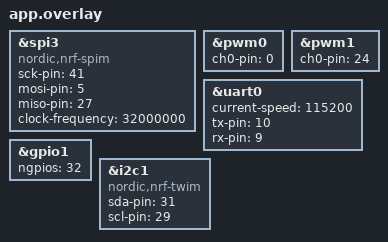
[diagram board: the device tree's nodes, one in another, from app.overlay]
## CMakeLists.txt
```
# SPDX-License-Identifier: Apache-2.0

cmake_minimum_required(VERSION 3.13.1)

find_package(Zephyr REQUIRED HINTS $ENV{ZEPHYR_BASE})
project(hello_world)

target_sources(app PRIVATE src/main.cpp src/display.cpp src/controller.cpp src/console.cpp src/sound.cpp src/invaders.cpp src/sprite.cpp src/mesh.c)
```

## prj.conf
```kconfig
# Incresed stack due to settings API usage
CONFIG_SYSTEM_WORKQUEUE_STACK_SIZE=2048
CONFIG_MAIN_STACK_SIZE=4096


CONFIG_BT=y
CONFIG_BT_DEBUG_LOG=y
# Security manager protocol support for pairing
CONFIG_BT_SMP=y
# used to sign authenticated data
CONFIG_BT_SIGNING=y
# select peripheral role
CONFIG_BT_PERIPHERAL=n

# enable GATT device information service
CONFIG_BT_DIS=n
# number of buffers available for GATT writing
CONFIG_BT_ATT_PREPARE_COUNT=5


# enables local privacy feature support (Random MAC)
CONFIG_BT_PRIVACY=n
# name that appears when browsing
CONFIG_BT_DEVICE_NAME="DublinMaker"

# 0x4c0 = generic control device = 1216
CONFIG_BT_DEVICE_APPEARANCE=1216
# disable updating of device name to prevent use of generic name
# disable run-time changing of device name
CONFIG_BT_DEVICE_NAME_DYNAMIC=n
# CONFIG_BT_DEVICE_NAME_MAX=65
CONFIG_BT_OBSERVER=y
CONFIG_BT_KEYS_OVERWRITE_OLDEST=y

CONFIG_BT_RX_STACK_SIZE=1280
CONFIG_BT_CTLR_DUP_FILTER_LEN=0
CONFIG_BT_OBSERVER=y
CONFIG_BT_BROADCASTER=y
CONFIG_BT_PHY_UPDATE=n
CONFIG_BT_DATA_LEN_UPDATE=n

CONFIG_BT_MESH=y
CONFIG_BT_MESH_RELAY=y
CONFIG_BT_MESH_SEG_BUFS=10
CONFIG_BT_MESH_SUBNET_COUNT=1
CONFIG_BT_MESH_APP_KEY_COUNT=2
CONFIG_BT_MESH_MODEL_GROUP_COUNT=2
CONFIG_BT_MESH_ADV_BUF_COUNT=3
CONFIG_BT_MESH_LOOPBACK_BUFS=8
CONFIG_BT_MESH_PB_ADV=n
CONFIG_BT_MESH_CFG_CLI=y
CONFIG_BT_MESH_BEACON_ENABLED=n
CONFIG_BT_MESH_RPL_STORE_TIMEOUT=600
CONFIG_BT_MESH_DEBUG=y

CONFIG_BT_SETTINGS=n
CONFIG_FLASH=y
CONFIG_FLASH_PAGE_LAYOUT=y
CONFIG_FLASH_MAP=y
CONFIG_NVS=y
CONFIG_SETTINGS=y



# enable SPI and GPIO
CONFIG_SPI=y
CONFIG_SPI_NRFX=y
CONFIG_GPIO=y
CONFIG_PWM=y
# By default P0.10 and P0.9 are configured for NFC and so not available for GPIO/UART use.  
# This switches them back to GPIO
CONFIG_NFCT_PINS_AS_GPIOS=y
# This doesn't seem to be working
CONFIG_GPIO_AS_PINRESET=n

# enable uart driver
CONFIG_SERIAL=y

# enable console
CONFIG_CONSOLE=y
CONFIG_UART_CONSOLE=y

CONFIG_CLOCK_CONTROL_NRF_K32SRC_RC=y
CONFIG_I2C=y

CONFIG_PM=n
CONFIG_HEAP_MEM_POOL_SIZE=8192
```

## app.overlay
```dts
&spi3 {
 compatible = "nordic,nrf-spim";
 status = "okay";
 sck-pin = <41>; // P1.09
 mosi-pin = <5>; // P0.05
 /* Redirecting MISO to a pin that is not connected on the microbit v2 board */
 miso-pin = <27>;
 clock-frequency = <32000000>;
};
&pwm0 {
	status = "okay";
	ch0-pin = <0>; 	
};
&pwm1 {
	status = "okay";
	ch0-pin = <24>; 	
};
&uart0 {
        status = "okay";
        current-speed = <115200>;
        tx-pin = <10>;
        rx-pin = <9>;
};

&gpio1 {
       status = "okay";
       ngpios = <32>;

};
&i2c1 {
	compatible = "nordic,nrf-twim";
    status = "okay";
    sda-pin = <31>; // P0.31 SDA on SAO connector
    scl-pin = <29>; // P0.29 SCL on SAO connector
};
```

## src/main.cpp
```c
#include <zephyr.h>
#include <sys/printk.h>

#include <settings/settings.h>

#include <bluetooth/bluetooth.h>
#include <bluetooth/mesh.h>
#include <bluetooth/hci.h>
#include <bluetooth/conn.h>
#include <bluetooth/uuid.h>
#include <bluetooth/gatt.h>
#include <drivers/pwm.h>
#include "display.h"
#include "controller.h"
#include "console.h"
#include "sound.h"
#include "invaders.h"
#include "mesh.h"

void sao_test()
{
	/* P0.24 - test ok, 
	 * P0.13 - test ok,
	 * P0.18 - NOT OK
	 * POWER subsystem at offset 0x40000000
	 * PSELRESET0 at offset 200
	 * PSELRESET1 at offset 204
	 * P1.09 - test ok
	*/
	static const struct device *gpio0,*gpio1;
	uint32_t * pselreset0 = (uint32_t *)0x40000200;
	uint32_t * pselreset1 = (uint32_t *)0x40000204; 
	*pselreset0=0x80000000;
	*pselreset1=0x80000000;
	gpio0=device_get_binding("GPIO_0");
	gpio1=device_get_binding("GPIO_1");
	gpio_pin_configure(gpio0,18,GPIO_OUTPUT);
	
	printk("0 = %x ",*pselreset0);
	printk("1 = %x\n",*pselreset1);
	while(1)
	{
		gpio_pin_set(gpio0,18,1);
		k_msleep(100);
		gpio_pin_set(gpio0,18,0);
		k_msleep(100);
	}
	
}
extern console Console;
#define TILE_WIDTH 30
#define TILE_HEIGHT 30
#define SPRITE_WIDTH 20
#define SPRITE_HEIGHT 25
const uint16_t tile[]={
0,
0,
0,
0,
0,
0,
0,
0,
0,
0,
0,
0,
0,
0,
0,
0,
0,
0,
0,
0,
0,
0,
0,
0,
0,
0,
0,
0,
0,
0,
0,
0,
0,
0,
0,
0,
0,
0,
0,
0,
0,
0,
0,
0,
0,
0,
0,
0,
0,
0,
0,
0,
0,
0,
0,
0,
0,
0,
0,
0,
248,
248,
248,
248,
248,
248,
248,
248,
248,
248,
248,
248,
248,
248,
248,
248,
248,
248,
248,
248,
248,
248,
248,
248,
248,
248,
248,
248,
248,
248,
248,
248,
248,
248,
248,
248,
248,
248,
248,
248,
248,
248,
248,
248,
248,
248,
248,
248,
248,
248,
248,
248,
248,
248,
248,
248,
248,
248,
248,
248,
57599,
57599,
57599,
57599,
57599,
57599,
57599,
57599,
57599,
57599,
57599,
57599,
57599,
57599,
57599,
57599,
57599,
57599,
57599,
57599,
57599,
57599,
57599,
57599,
57599,
57599,
57599,
57599,
57599,
57599,
57599,
57599,
57599,
57599,
57599,
57599,
57599,
57599,
57599,
57599,
57599,
57599,
57599,
57599,
57599,
57599,
57599,
57599,
57599,
57599,
57599,
57599,
57599,
57599,
57599,
57599,
57599,
57599,
57599,
57599,
57351,
57351,
57351,
57351,
57351,
57351,
57351,
57351,
57351,
57351,
57351,
57351,
57351,
57351,
57351,
57351,
57351,
57351,
57351,
57351,
57351,
57351,
57351,
57351,
57351,
57351,
57351,
57351,
57351,
57351,
57351,
57351,
57351,
57351,
57351,
57351,
57351,
57351,
57351,
57351,
57351,
57351,
57351,
57351,
57351,
57351,
57351,
57351,
57351,
57351,
57351,
57351,
57351,
57351,
57351,
57351,
57351,
57351,
57351,
57351,
65287,
65287,
65287,
65287,
65287,
65287,
65287,
65287,
65287,
65287,
65287,
65287,
65287,
65287,
65287,
65287,
65287,
65287,
65287,
65287,
65287,
65287,
65287,
65287,
65287,
65287,
65287,
65287,
65287,
65287,
65287,
65287,
65287,
65287,
65287,
65287,
65287,
65287,
65287,
65287,
65287,
65287,
65287,
65287,
65287,
65287,
65287,
65287,
65287,
65287,
65287,
65287,
65287,
65287,
65287,
65287,
65287,
65287,
65287,
65287,
7936,
7936,
7936,
7936,
7936,
7936,
7936,
7936,
7936,
7936,
7936,
7936,
7936,
7936,
7936,
7936,
7936,
7936,
7936,
7936,
7936,
7936,
7936,
7936,
7936,
7936,
7936,
7936,
7936,
7936,
7936,
7936,
7936,
7936,
7936,
7936,
7936,
7936,
7936,
7936,
7936,
7936,
7936,
7936,
7936,
7936,
7936,
7936,
7936,
7936,
7936,
7936,
7936,
7936,
7936,
7936,
7936,
7936,
7936,
7936,
8184,
8184,
8184,
8184,
8184,
8184,
8184,
8184,
8184,
8184,
8184,
8184,
8184,
8184,
8184,
8184,
8184,
8184,
8184,
8184,
8184,
8184,
8184,
8184,
8184,
8184,
8184,
8184,
8184,
8184,
8184,
8184,
8184,
8184,
8184,
8184,
8184,
8184,
8184,
8184,
8184,
8184,
8184,
8184,
8184,
8184,
8184,
8184,
8184,
8184,
8184,
8184,
8184,
8184,
8184,
8184,
8184,
8184,
8184,
8184,
4348,
4348,
4348,
4348,
4348,
4348,
4348,
4348,
4348,
4348,
4348,
4348,
4348,
4348,
4348,
4348,
4348,
4348,
4348,
4348,
4348,
4348,
4348,
4348,
4348,
4348,
4348,
4348,
4348,
4348,
4348,
4348,
4348,
4348,
4348,
4348,
4348,
4348,
4348,
4348,
4348,
4348,
4348,
4348,
4348,
4348,
4348,
4348,
4348,
4348,
4348,
4348,
4348,
4348,
4348,
4348,
4348,
4348,
4348,
4348,
61575,
61575,
61575,
61575,
61575,
61575,
61575,
61575,
61575,
61575,
61575,
61575,
61575,
61575,
61575,
61575,
61575,
61575,
61575,
61575,
61575,
61575,
61575,
61575,
61575,
61575,
61575,
61575,
61575,
61575,
61575,
61575,
61575,
61575,
61575,
61575,
61575,
61575,
61575,
61575,
61575,
61575,
61575,
61575,
61575,
61575,
61575,
61575,
61575,
61575,
61575,
61575,
61575,
61575,
61575,
61575,
61575,
61575,
61575,
61575,
6342,
6342,
6342,
6342,
6342,
6342,
6342,
6342,
6342,
6342,
6342,
6342,
6342,
6342,
6342,
6342,
6342,
6342,
6342,
6342,
6342,
6342,
6342,
6342,
6342,
6342,
6342,
6342,
6342,
6342,
6342,
6342,
6342,
6342,
6342,
6342,
6342,
6342,
6342,
6342,
6342,
6342,
6342,
6342,
6342,
6342,
6342,
6342,
6342,
6342,
6342,
6342,
6342,
6342,
6342,
6342,
6342,
6342,
6342,
6342,
128,
128,
128,
128,
128,
128,
128,
128,
128,
128,
128,
128,
128,
128,
128,
128,
128,
128,
128,
128,
128,
128,
128,
128,
128,
128,
128,
128,
128,
128,
128,
128,
128,
128,
128,
128,
128,
128,
128,
128,
128,
128,
128,
128,
128,
128,
128,
128,
128,
128,
128,
128,
128,
128,
128,
128,
128,
128,
128,
128,
8068,
8068,
8068,
8068,
8068,
8068,
8068,
8068,
8068,
8068,
8068,
8068,
8068,
8068,
8068,
8068,
8068,
8068,
8068,
8068,
8068,
8068,
8068,
8068,
8068,
8068,
8068,
8068,
8068,
8068,
8068,
8068,
8068,
8068,
8068,
8068,
8068,
8068,
8068,
8068,
8068,
8068,
8068,
8068,
8068,
8068,
8068,
8068,
8068,
8068,
8068,
8068,
8068,
8068,
8068,
8068,
8068,
8068,
8068,
8068,
252,
252,
252,
252,
252,
252,
252,
252,
252,
252,
252,
252,
252,
252,
252,
252,
252,
252,
252,
252,
252,
252,
252,
252,
252,
252,
252,
252,
252,
252,
252,
252,
252,
252,
252,
252,
252,
252,
252,
252,
252,
252,
252,
252,
252,
252,
252,
252,
252,
252,
252,
252,
252,
252,
252,
252,
252,
252,
252,
252,
4228,
4228,
4228,
4228,
4228,
4228,
4228,
4228,
4228,
4228,
4228,
4228,
4228,
4228,
4228,
4228,
4228,
4228,
4228,
4228,
4228,
4228,
4228,
4228,
4228,
4228,
4228,
4228,
4228,
4228,
4228,
4228,
4228,
4228,
4228,
4228,
4228,
4228,
4228,
4228,
4228,
4228,
4228,
4228,
4228,
4228,
4228,
4228,
4228,
4228,
4228,
4228,
4228,
4228,
4228,
4228,
4228,
4228,
4228,
4228,
65287,
65287,
65287,
65287,
65287,
65287,
65287,
65287,
65287,
65287,
65287,
65287,
65287,
65287,
65287,
65287,
65287,
65287,
65287,
65287,
65287,
65287,
65287,
65287,
65287,
65287,
65287,
65287,
65287,
65287,
65287,
65287,
65287,
65287,
65287,
65287,
65287,
65287,
65287,
65287,
65287,
65287,
65287,
65287,
65287,
65287,
65287,
65287,
65287,
65287,
65287,
65287,
65287,
65287,
65287,
65287,
65287,
65287,
65287,
65287,
};
void drawTile(int row, int col)
{
	Console.Display.putImage(row*TILE_WIDTH,col*TILE_HEIGHT,TILE_WIDTH,TILE_HEIGHT,(uint16_t *)&tile[0]);
}
void drawTile2(int row, int col)
{
	Console.Display.fillRectangle(row*TILE_WIDTH,col*TILE_HEIGHT,TILE_WIDTH,TILE_HEIGHT,0xffff);
}
void drawLandscape()
{

	int row,col;
	
	for (row=0;row<SCREEN_HEIGHT/TILE_HEIGHT;row++)
	{
		for (col=0;col<SCREEN_WIDTH/TILE_WIDTH;col++)
		{
			drawTile(row,col);
		}
	}
}

uint8_t dirty_flags[]={0,0,0,0,0,0,0,0};
void flagDirty(int row, int col)
{
	dirty_flags[row] |= (1 << col);
}
void flagClean(int row, int col)
{
	dirty_flags[row] &= ~(1 << col);
}
int isDirty(int row, int col)
{
	if (dirty_flags[row] & (1 << col))
		return 1;
	else
		return 0;
}
void check_for_overlap(int x,int y, int w, int h)
{
	// incoming arguments are the bounding rectangle for a sprite
	// This function checks to see if that sprite overlaps each
	// background screen tile.
	int row,col;
	for (row=0;row<SCREEN_HEIGHT/TILE_HEIGHT;row++)
	{
		for (col=0;col<SCREEN_WIDTH/TILE_WIDTH;col++)
		{
			
			// check top left corner
			if ((x >=row*TILE_WIDTH) && (y >= col*TILE_HEIGHT) &&
				((x) < (row+1)*TILE_WIDTH) && ((y) < (col+1)*TILE_HEIGHT) )
			{
				flagDirty(row,col);				
			}
			// check top right
			if (((x+w) >=row*TILE_WIDTH) && (y >= col*TILE_HEIGHT) &&
				((x+w) < (row+1)*TILE_WIDTH) && ((y) < (col+1)*TILE_HEIGHT) )
			{
				flagDirty(row,col);				
			}
			// check bottom left corner
			if ((x >=row*TILE_WIDTH) && ((y+h) >= col*TILE_HEIGHT) &&
				((x) < (row+1)*TILE_WIDTH) && ((y+h) < (col+1)*TILE_HEIGHT) )
			{
				flagDirty(row,col);				
			}
			// check bottom right
			if (((x+w) >=row*TILE_WIDTH) && ((y+w) >= col*TILE_HEIGHT) &&
				((x+w) < (row+1)*TILE_WIDTH) && ((y+w) < (col+1)*TILE_HEIGHT) )
			{
				flagDirty(row,col);				
			}
		}
	}	
}
void drawCharacter(int x, int y)
{
	
	// 1f00 = blue
	// 00f8 = red
	// e007 = green
	
	Console.Display.fillRectangle(x,y,SPRITE_WIDTH,SPRITE_HEIGHT,4);
}
void moveCharacter()
{
	int x,y;
	int row,col;
	x = 0; y = 0;
	while(1)
	{

		for (row=0;row<SCREEN_HEIGHT/TILE_HEIGHT;row++)
		{
			for (col=0;col<SCREEN_WIDTH/TILE_WIDTH;col++)
			{
				if (isDirty(row,col))
				{
					drawTile(row,col);
					flagClean(row,col);
				}
			}
		}		
		drawCharacter(x,y);
		k_msleep(70);
		check_for_overlap(x,y,SPRITE_WIDTH,SPRITE_HEIGHT);
		x++;
		if (x >= (SCREEN_WIDTH-SPRITE_WIDTH))
			x=0;
		y++;
		if (y >= (SCREEN_HEIGHT-SPRITE_HEIGHT))
			y = 0;
		
	}
}
void main(void)
{
	
	
	int ret;
	int count=0;	
	ret = Console.begin();	
	uint8_t msg_count = 0;
	mesh_begin();
	if (ret < 0)
	{
		printk("\nError initializing console.  Error code = %d\n",ret);
		while(1);
	}	
	//playInvaders(0);		
	drawLandscape();
	moveCharacter();
	while(1)
	{
		
		//printk("Hello World! %s\n", CONFIG_BOARD);
       //Display.drawRectangle(random(0,119),random(0,119),random(0,120),random(0,120),random(0,0xffff));                                
       //Console.Display.fillRectangle(Console.random(0,240),Console.random(0,240),Console.random(0,240),Console.random(0,240),Console.random(0,0xffff));                   
       // display_drawCircle(random(0,240),random(0,240),random(0,135),random(0,0xffff));
        //Display.fillCircle(random(0,240),random(0,135),random(0,120),random(0,0xffff));
        count++;
        if (count >= 50) 
        {
            //Console.Display.fillRectangle(0,0,SCREEN_WIDTH,SCREEN_HEIGHT,0);
			
		//	Console.Display.print("Starting over",sizeof("Starting over")-1,20,60,0xffff,0);
            count = 0;
		//	sendDMBMessage(msg_count++);

			//printk("restarting\n");
			printk("Buttons = %x\n",Console.Controller.getButtonState());
 		//	printk("Buttons = %d\r\n",Console.Controller.getButtonState());
        }
        
	}
}
```

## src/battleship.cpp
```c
#include <zephyr.h>
#include <sys/printk.h>
#include "mesh.h"
#include "display.h"
#include "console.h"
#include "controller.h"
#include "battleship.h"
#include "font5x7.h"
void ship::place(int len, int row, int col, int orientation)
{
    this->len = len;
    this->row = row;
    this->col = col;
    this->orientation = orientation;
    
    state = 0;
}
int ship::contains(int row, int col)
{
    // returns 1 if the ship occupies the square at this row, column
    // otherwise returns 0
    int return_value = 0;
    if (orientation == 0)
    {
        // Horizontal
        if (this->row == row) 
        {
            // same row.
            if ( (col >= this->col) && (col < (this->col+this->len)))
                return_value = 1; // it is within
        }
    }
    else
    {
        // Vertical
        if (this->col == col)
        {
            if ( (row >= this->row) && (row < (this->row+this->len)))
                return_value = 1; // it is within
        }
    }
    return return_value; // not within the bounds of this ship
}
int ship::overlaps(int len, int row, int col, int orientation)
{
    // returns 1 if the ship described by the parameters overlaps
    // this ship - uses for initial ship placement.
    // otherwise returns 0
    int return_value = 0;
    if (orientation == 0)
    {
        // Horizontal
        for (int count = 0; count < len; count++)
        {
            if (this->contains(row,col+count))
                return_value = 1;
        }
    }
    else
    {
        // Vertical
        for (int count = 0; count < len; count++)
        {
            if (this->contains(row+count,col))
                return_value = 1;
        }
    }
    return return_value;
}
/* each square can have the following properties:
 * Empty
 * Your ship (ship_id with particular bit pattern for you/them)
 * Their ship
 * Your ship hit
 * Their ship hit
 * uint8_t my_ship_map[10][10];
 */

void battleship()
{
    int row,col;
    uint8_t map[10][10];
    int ship_counter = 0;
    int Done=0;
    uint16_t target=0;
    int my_ship_hit_counter = 0;
    int their_ship_hit_counter = 0;
    int total_hits;
    total_hits = (CARRIER_COUNT*CARRIER_SQUARES) + (BATTLESHIP_COUNT*BATTLESHIP_SQUARES)+(SUBMARINE_COUNT*SUBMARINE_SQUARES)+(PATROL_BOAT_COUNT*PATROL_BOAT_SQUARES); 
	mesh_clearReplay();

    Console.Display.clear();
    Console.Display.printX2("Target node: ", 13,0,0,Console.Display.RGBToWord(0xff,0xff,0), Console.Display.RGBToWord(0,0,0) );
    while(!Done)
    {
        Console.Display.printX2(target,0,1+FONT_HEIGHT*2, Console.Display.RGBToWord(0xff,0xff,0), Console.Display.RGBToWord(0,0,0) );
        uint16_t key=0;
        while(key == 0)
        {
            key=Console.Controller.getButtonState();
            k_msleep(50);
        }
        switch(key)
        {
            case Console.Controller.Up :
            {
                target++;
                break;
            }
            case Console.Controller.Down :
            {
                target--;
                break;
            }
            case Console.Controller.A :
            {
                Done=1;
                break;
            }
            case Console.Controller.B :
            {
                Done=2;
                break;
            }
        }
        k_msleep(100);
    }

    ship Ships[CARRIER_COUNT+BATTLESHIP_COUNT+SUBMARINE_COUNT+PATROL_BOAT_COUNT];
    Console.Display.clear();
    
    for (row=0;row<10;row++)
    {
        Console.Display.drawLine(0,row*(SCREEN_HEIGHT/10),SCREEN_WIDTH,row*(SCREEN_HEIGHT/10),Console.Display.RGBToWord(0xf,0xf,0xff));
    }
    for (col=0;col<10;col++)
    {
        Console.Display.drawLine(col*(SCREEN_WIDTH/10),0,col*(SCREEN_WIDTH/10),SCREEN_HEIGHT,Console.Display.RGBToWord(0xf,0xf,0xff));
    }
    Console.Display.drawLine(0,SCREEN_HEIGHT-1,SCREEN_WIDTH-1,SCREEN_HEIGHT-1,Console.Display.RGBToWord(0xf,0xf,0xff));
    Console.Display.drawLine(SCREEN_WIDTH-1,0,SCREEN_WIDTH-1,SCREEN_HEIGHT-1,Console.Display.RGBToWord(0xf,0xf,0xff));
    for (row=0;row<10;row++)
    {
        for (col=0;col<10;col++)
            map[row][col]=0;
    }
    // start placing ships
    // Aircraft carrier first as it will be hardest to position.
    int orientation = Console.random(0,2);
    if (orientation == 0)
    {
        // Horizontal
        col=Console.random(0,CARRIER_SQUARES);
        row=Console.random(0,10);
        for (int i=0;i<CARRIER_SQUARES;i++)
            map[row][col+i]=MY_SHIP_NORMAL;
    }
    else
    {        
        col=Console.random(0,10);
        row=Console.random(0,CARRIER_SQUARES);
        for (int i=0;i<CARRIER_SQUARES;i++)
            map[row+i][col]=MY_SHIP_NORMAL;
    }
    Ships[ship_counter].place(CARRIER_SQUARES,row,col,orientation);
    ship_counter++;
    
    // Place Battleships
    int len = BATTLESHIP_SQUARES;    
    for (int ship_class_count = 0; ship_class_count < BATTLESHIP_COUNT; ship_class_count++)
    {
        Done = 0;    
        while( !Done )
        {
            // Attempt to get an empty part of the board;
            orientation = Console.random(0,2);
            if (orientation == 0)
            {
                // Horizontal
                col=Console.random(0,len);
                row=Console.random(0,10);
            }
            else
            {        
                col=Console.random(0,10);
                row=Console.random(0,len);
            }
            int invalid = 0;
            for (int ship_index=0; ship_index < ship_counter; ship_index++)
            {
                if (Ships[ship_index].overlaps(len,row,col,orientation))
                    invalid = 1;
                
            }
            if (invalid == 0)
                Done = 1;
        }
        if (orientation == 0)
        {
            for (int i=0;i<len;i++)
                map[row][col+i]=MY_SHIP_NORMAL;
        }
        else
        {
            for (int i=0;i<len;i++)
                map[row+i][col]=MY_SHIP_NORMAL;
        }
        Ships[ship_counter].place(BATTLESHIP_SQUARES,row,col,orientation);
        ship_counter++;
    }
    
    // Place submarines
    len = SUBMARINE_SQUARES;
    for (int ship_class_count = 0; ship_class_count < SUBMARINE_COUNT; ship_class_count++)
    {
        Done = 0;    
        while( !Done )
        {
            // Attempt to get an empty part of the board;
            orientation = Console.random(0,2);
            if (orientation == 0)
            {
                // Horizontal
                col=Console.random(0,len);
                row=Console.random(0,10);
            }
            else
            {        
                col=Console.random(0,10);
                row=Console.random(0,len);
            }
            int invalid = 0;
            for (int ship_index=0; ship_index < ship_counter; ship_index++)
            {
                if (Ships[ship_index].overlaps(len,row,col,orientation))
                    invalid = 1;
                
            }
            if (invalid == 0)
                Done = 1;
        }
        if (orientation == 0)
        {
            for (int i=0;i<len;i++)
                map[row][col+i]=MY_SHIP_NORMAL;
        }
        else
        {
            for (int i=0;i<len;i++)
                map[row+i][col]=MY_SHIP_NORMAL;
        }
        Ships[ship_counter].place(SUBMARINE_SQUARES,row,col,orientation);
        ship_counter++;
    }

    // Place Patrol boats
    len = PATROL_BOAT_SQUARES;    
    for (int ship_class_count = 0; ship_class_count < PATROL_BOAT_COUNT; ship_class_count++)
    {
        Done = 0;    
        while( !Done )
        {
            // Attempt to get an empty part of the board;
            orientation = Console.random(0,2);
            if (orientation == 0)
            {
                // Horizontal
                col=Console.random(0,len);
                row=Console.random(0,10);
            }
            else
            {        
                col=Console.random(0,10);
                row=Console.random(0,len);
            }
            int invalid = 0;
            for (int ship_index=0; ship_index < ship_counter; ship_index++)
            {
                if (Ships[ship_index].overlaps(len,row,col,orientation))
                    invalid = 1;
                
            }
            if (invalid == 0)
                Done = 1;
        }
        if (orientation == 0)
        {
            for (int i=0;i<len;i++)
                map[row][col+i]=MY_SHIP_NORMAL;
        }
        else
        {
            for (int i=0;i<len;i++)
                map[row+i][col]=MY_SHIP_NORMAL;
        }
        Ships[ship_counter].place(PATROL_BOAT_SQUARES,row,col,orientation);
        ship_counter++;
    }
    
    
    
    uint16_t x,y,old_row,old_col;
    x=y=old_row=old_col=0;
    Done = 0;
    while(!Done)
    {
        
        // Hide the old dot
        x = old_col * (SCREEN_WIDTH/10)+SCREEN_WIDTH/20;
        y = old_row * (SCREEN_WIDTH/10)+SCREEN_WIDTH/20;
        Console.Display.fillCircle(x,y,8,Console.Display.RGBToWord(0,0,0));
        for (int map_row=0;map_row<10;map_row++)
        {
            for (int map_col=0;map_col < 10; map_col++)
            {
                if (map[map_row][map_col]==MY_SHIP_NORMAL)
                {
                    Console.Display.fillRectangle(map_col*(SCREEN_WIDTH/10),map_row*(SCREEN_HEIGHT/10),SCREEN_WIDTH/10,SCREEN_HEIGHT/10,Console.Display.RGBToWord(0xff,0xff,0xff));
                }
                else if (map[map_row][map_col]==MY_SHIP_HIT)
                {
                    Console.Display.fillRectangle(map_col*(SCREEN_WIDTH/10),map_row*(SCREEN_HEIGHT/10),SCREEN_WIDTH/10,SCREEN_HEIGHT/10,Console.Display.RGBToWord(0xff,0xf,0xf));
                }
                else if (map[map_row][map_col]==THEIR_SHIP_NORMAL)
                {
                    Console.Display.fillRectangle(map_col*(SCREEN_WIDTH/10),map_row*(SCREEN_HEIGHT/10),SCREEN_WIDTH/10,SCREEN_HEIGHT/10,Console.Display.RGBToWord(0x0,0xff,0xff));                    
                }
                else if (map[map_row][map_col]==THEIR_SHIP_HIT)
                {
                    Console.Display.fillRectangle(map_col*(SCREEN_WIDTH/10),map_row*(SCREEN_HEIGHT/10),SCREEN_WIDTH/10,SCREEN_HEIGHT/10,Console.Display.RGBToWord(0xff,0x0,0xff));                    
                }
            }
        }        
        // show the new dot        
        x = col * (SCREEN_WIDTH/10)+SCREEN_WIDTH/20;
        y = row * (SCREEN_WIDTH/10)+SCREEN_WIDTH/20;
        Console.Display.fillCircle(x,y,8,Console.Display.RGBToWord(0x1f,0x1f,0xff));
        old_row = row;
        old_col = col;
        uint16_t key=0;
        while(key == 0)
        {
            key=Console.Controller.getButtonState();
            if (DMBGameMessageReceived)
            {
                // incoming message from the other player.
                uint16_t target_row, target_col, hit;
                DMBGameMessageReceived = 0;
                hit = 0;
                target_row=DMBGameMailBox.Message[0];
                target_col=DMBGameMailBox.Message[1];
                printk("Target %d, %d \n",target_row,target_col);
                for (int ship_counter = 0; ship_counter < (CARRIER_COUNT+BATTLESHIP_COUNT+SUBMARINE_COUNT+PATROL_BOAT_COUNT); ship_counter++)
                {
                    if (Ships[ship_counter].contains(target_row,target_col))  
                    {
                        hit = 1;
                        if (map[target_row][target_col] != MY_SHIP_HIT)
                        {
                            my_ship_hit_counter++;
                        }
                        if (my_ship_hit_counter >= total_hits)
                        {
                            Console.Display.clear();
                            Console.Display.printX2("You lose!",9,5,20,Console.Display.RGBToWord(0xff,0xf,0xf),Console.Display.RGBToWord(0,0,0));
							Done=1;
                        }
                        map[target_row][target_col]=MY_SHIP_HIT;
                        // Fill in the square with the MY_SHIP_HIT colour  
                        Console.Display.fillRectangle(target_col*(SCREEN_WIDTH/10),target_row*(SCREEN_HEIGHT/10),SCREEN_WIDTH/10,SCREEN_HEIGHT/10,Console.Display.RGBToWord(0xff,0xf,0xf));
                    }
                }
                dmb_message response;
                response.Message[0]=hit;
                
                sendDMBGameResponseMessage(target,&response);
            }
            k_msleep(50);
        }
        
        switch(key)
        {
            case Console.Controller.Up :
            {
                row--;
                break;
            }
            case Console.Controller.Down :
            {
                row++;
                break;
            }
            case Console.Controller.Left :
            {
                col--;
                break;
            }
            case Console.Controller.Right :
            {
                col++;
                break;
            }
            case Console.Controller.A :
            {
                // Send a message to the opponent with row/col and wait for a reply (with timeout)
                DMBGameMessageResponseReceived = 0;
                dmb_message msg;
                msg.Message[0]=row;
                msg.Message[1]=col;
                sendDMBGameMessage(target,&msg);
                // wait for a reply
                uint32_t Timeout=100;
                while( (!DMBGameMessageResponseReceived) && (Timeout--))
                    k_msleep(10);
                if (DMBGameMessageResponseReceived)
                {                    
                    if (DMBGameResponseMailBox.Message[0]==1) 
                    {
                        // It's a hit 
                        if (map[row][col] != THEIR_SHIP_HIT)
                        {
                            their_ship_hit_counter++;
                        }
                        if (their_ship_hit_counter >= total_hits)
                        {
                            Console.Display.clear();
                            Console.Display.printX2("You win!",8,5,20,Console.Display.RGBToWord(0xff,0xff,0),Console.Display.RGBToWord(0,0,0));
							while(Console.Controller.getButtonState()==0)
								k_msleep(50);
							return;
							
                        }
                        map[row][col]=THEIR_SHIP_HIT;
                        Console.Display.fillRectangle(col*(SCREEN_WIDTH/10),row*(SCREEN_HEIGHT/10),SCREEN_WIDTH/10,SCREEN_HEIGHT/10,Console.Display.RGBToWord(0xff,0x0,0xff));     
                    }
                    else
                    {
                       // if (map[row][col] != 0)
                        {
                            map[row][col]=THEIR_SHIP_NORMAL;
                        }
                    }
                }
                else 
                {
                    printk("Message response timeout\n");
                }
                break;
            }
        }
        k_msleep(50);
        if (row < 0)
            row=0;
        if (col < 0)
            col = 0;
        if (row > 9)
            row=9;
        if (col > 9)
            col=9;
       
    }
    while(Console.Controller.getButtonState()==0)
	{
		k_msleep(50);
	}
	return;
    
}
```

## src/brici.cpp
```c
#include <stdint.h>
#include "../include/STM32F0x0.h"
#include "console.h"
#include "spi.h"
#include "timer.h"
#include "sprite.h"
#include "brick.h"
#include "brici.h"
#define DEMO_HITS 10
void ClassicBrici()
{   
    #define Brick_Width 30
    #define Brick_Height 10
    #define BRICK_COUNT ( (3*SCREEN_WIDTH) / Brick_Width )
    Console.fillRectangle(0,0,SCREEN_WIDTH-1,SCREEN_HEIGHT-1,0);
    brick Bricks[BRICK_COUNT];
    uint16_t RowCount=0;
    uint32_t Brick_Count = BRICK_COUNT;
    uint32_t Index=0;
    uint16_t x,y,w,h;
    uint16_t r,g,b;
    uint16_t Colour;
    for (Index=0;Index < Brick_Count/3; Index++)
    {
        r=255;
        b=64;
        g=255;
        x=RowCount*Brick_Width;
        y=50;
        Bricks[Index].define(x,y,Brick_Width,Brick_Height,COLOUR(r,g,b));
        RowCount++;
    }
    RowCount = 0;
    for (Index=Brick_Count/3;Index < (2*Brick_Count)/3; Index++)
    {
        r=64;
        b=64;
        g=255;
        x=RowCount*Brick_Width;
        y=50+Brick_Height;
        Bricks[Index].define(x,y,Brick_Width,Brick_Height,COLOUR(r,g,b));
        RowCount++;
    }
    RowCount = 0;
    for (Index=(2*Brick_Count)/3;Index < Brick_Count; Index++)
    {
        r=64;
        b=255;
        g=64;
        x=RowCount*Brick_Width;
        y=50+2*Brick_Height;
        Bricks[Index].define(x,y,Brick_Width,Brick_Height,COLOUR(r,g,b));
        RowCount++;
    }
    Brici(Bricks,Brick_Count,30,0);
}
void Brici(brick *Bricks, uint16_t Brick_Count, uint16_t BatWidth,uint16_t demo_mode)
{
    
    
    brick Bat(0, SCREEN_HEIGHT-20, BatWidth, 3,COLOUR(255,255,255));    
    brick Ball(SCREEN_WIDTH/2, SCREEN_HEIGHT/2, 3, 3,COLOUR(255,255,255));
#define MAX_BRICI_LEVELS 4
    int Level = MAX_BRICI_LEVELS;
    int LevelComplete = 0;
    int8_t BallCount = 5;
    uint8_t Index;
    int8_t BallXVelocity = 1;
    int8_t BallYVelocity = 1;   
    uint32_t BatHits=0;

    while (Level > 0)
    {
        for (Index = 0; Index < Brick_Count; Index++)
        {
            Bricks[Index].show();
            if (!demo_mode)
                Console.drawRectangle(Bricks[Index].getX(),Bricks[Index].getY(),Bricks[Index].getWidth(),Bricks[Index].getHeight(),0);
        }
        Ball.move(Console.random(10, SCREEN_WIDTH-10), SCREEN_HEIGHT/2);
        if (Console.random(0,2) > 0)
            BallXVelocity = 1;
        else
            BallXVelocity = -1;
        LevelComplete = 0;
        BallYVelocity = -1;        
        for (Index = BallCount; Index > 0; Index--)
            Console.fillRectangle(SCREEN_WIDTH - Index * 15, SCREEN_HEIGHT-10, 10, 10, RGBToWord(0xff, 0xf, 0xf));        
        Ball.show();
        Bat.show();
        Console.print("Level", 5, 5, SCREEN_HEIGHT-10, RGBToWord(0xff, 0xff, 0xff), RGBToWord(0, 0, 0));
        Console.print(MAX_BRICI_LEVELS - Level + 1, 60, SCREEN_HEIGHT-10, RGBToWord(0xff, 0xff, 0xff), RGBToWord(0, 0, 0));
        
        while (!LevelComplete)
        {            
            if (Console.Controller.getButtonState() & Console.Controller.Right)
            {
                // Move right
                if (Bat.getX() < (SCREEN_WIDTH - Bat.getWidth()))
                {
                    Bat.move(Bat.getX() + 2, Bat.getY()); // Move the bat faster than the ball
                }
            }
            
            if (Console.Controller.getButtonState() & Console.Controller.Left)
            {
                // Move left
                if (Bat.getX() > 0)
                {
                    Bat.move(Bat.getX() - 2, Bat.getY()); // Move the bat faster than the ball
                }
            }
            
            if (Bat.touching(Ball.getX() + Ball.getWidth() / 2, Ball.getY() + Ball.getHeight() / 2))
            { // Ball bounced off the bat
                BallYVelocity = -BallYVelocity; 
                if (!demo_mode)
                    Console.Sound.playTone(200,20);
                if (demo_mode) 
                {
                    if (Console.Controller.getButtonState())
                    {
                        // Someone pushed a button - get out of demo mode
                        return;
                    }
                    BatHits++;                
                    if (BatHits >= DEMO_HITS)
                    {
                       return;      
                    }
                }
            }                        
            Ball.move(Ball.getX() + BallXVelocity, Ball.getY() + BallYVelocity); // update ball position
            if (Ball.getX() == 2) // bounced off left side?
            {
                BallXVelocity = -BallXVelocity;
                if (!demo_mode)
                    Console.Sound.playTone(400,20);
            }
            if (Ball.getX() == SCREEN_WIDTH - 2) // bounced off right side?
            {
                BallXVelocity = -BallXVelocity;
                if (!demo_mode)
                    Console.Sound.playTone(400,20);
            }
            if (Ball.getY() == 2)  // bounced off top? (behind the block)
            {
                BallYVelocity = -BallYVelocity;
                if (!demo_mode)
                    Console.Sound.playTone(400,20);
            }
            
            if (Ball.getY() >= Bat.getY() + Bat.getHeight() + 2)  // Did the ball go behind the bat?
            {
                BallCount--;  // Lost a ball!
                if (BallCount == 0) // Any left?
                {
                    // Nope: hard luck, game over
                    Console.fillRectangle(0, 0, SCREEN_WIDTH, SCREEN_HEIGHT, 0);
                    Console.print("GAME OVER", 9, 80, 100, RGBToWord(0xff, 0xff, 0xff), 0);
                    Console.print("Fire to restart", 15, 60, 120, RGBToWord(0xff, 0xff, 0), RGBToWord(0, 0, 0));
                    while (!(Console.Controller.getButtonState() & Console.Controller.Fire))
                        Console.Timer.sleep(10);
                    return;
                }
                // start a new ball moving in a random way
                if (Console.random(0,100) & 1)
                    BallXVelocity = 1;
                else
                    BallXVelocity = -1;
                BallYVelocity = -1;
                Ball.move(Console.random(10, SCREEN_WIDTH - 10), Console.random(90, 120));
                Console.fillRectangle(SCREEN_WIDTH-5*15, SCREEN_HEIGHT-10, 120, 10, 0);  // wipe out the remaining lives area
                for (Index = BallCount; Index > 0; Index--) //  draw remaining lives
                    Console.fillRectangle(SCREEN_WIDTH - Index * 15, SCREEN_HEIGHT-10, 10, 10, RGBToWord(0xff, 0xf, 0xf));
                
            }
            LevelComplete = 1;
            // Check to see if the ball has hit any of the blocks
            for (Index = 0; Index < Brick_Count; Index++)
            {
                if (Bricks[Index].visible()) // any blocks left?
                    LevelComplete = 0; // If yes then the level is not complete
                    
                int touch = 0;
                // Check all 4 corners of the ball for touching
                touch += Bricks[Index].touching(Ball.getX(), Ball.getY());
                if (touch == 0)
                    touch = Bricks[Index].touching(Ball.getX()+2, Ball.getY());
                if (touch == 0)
                    touch = Bricks[Index].touching(Ball.getX(), Ball.getY()+2);
                if (touch == 0)
                    touch = Bricks[Index].touching(Ball.getX()+2, Ball.getY()+2);
                if (touch)
                { // Block hit so hide it.
                    Bricks[Index].hide();  
                    if ( (touch == 1) || (touch == 3) )
                        BallYVelocity = -BallYVelocity;
                    if ( (touch == 2) || (touch == 4) )
                        BallXVelocity = -BallXVelocity;
                    if (!demo_mode)
                        Console.Sound.playTone(1000,20);
                }
            }
            // No Blocks left, Move to next level.
            if ((LevelComplete == 1) && (Level > 0))
            {
                Level--;
                Ball.hide();
                Console.print("Level", 5, 5, SCREEN_HEIGHT-10, RGBToWord(0xff, 0xff, 0xff), RGBToWord(0, 0, 0));
                Console.print(MAX_BRICI_LEVELS - Level + 1, 60, SCREEN_HEIGHT-10, RGBToWord(0xff, 0xff, 0xff), RGBToWord(0, 0, 0));                
            }
            if (!demo_mode)
            {
                Console.Timer.sleep(Level+5); // Slow the game to human speed                
            }
            else
            {
                Console.Timer.sleep(5); // Slow the game to human speed                
            }
            Bat.redraw(); // redraw bat as it might have lost a pixel due to collisions          
        }
    }
}
```

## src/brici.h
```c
void ClassicBrici(void);
void Brici(brick *Bricks, uint16_t Brick_Count, uint16_t BatWidth,uint16_t demo_mode);
```

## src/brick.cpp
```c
    #include <stdint.h>
#include "console.h"
#include "sprite.h"
#include "brick.h"

brick::brick( uint16_t x, uint16_t y, uint16_t w, uint16_t h,  uint16_t fillcolour)
{
    
    this->Visible = 0;        
    define(x,y,w,h,fillcolour);
}
brick::brick()
{
    this->Visible = 0;
}

void brick::define( uint16_t x, uint16_t y, uint16_t w, uint16_t h,uint16_t fillcolour)
{       
    this->fillcolour = fillcolour;
    this->Visible = 0;    
    this->w = w;
    this->h = h;
    this->X = x;
    this->Y = y;    
}

void brick::show()
{
    //if (!Visible)
    {                
        Console.fillRectangle(X,Y,w,h,fillcolour);           
    }
    Visible=1;
    
}

void brick::hide()
{
    if (Visible)
    {
        // assumes a black backgound (colour = 0)
        Console.fillRectangle(X,Y,w,h,0);
    }
    Visible = 0;
}
```

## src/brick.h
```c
#include <stdint.h>
#include "console.h"
#include "sprite.h"
class brick: public sprite {
public:
    brick( uint16_t x, uint16_t y, uint16_t w, uint16_t h, uint16_t fillcolour);    
    brick();
    void define(uint16_t x, uint16_t y, uint16_t w, uint16_t h, uint16_t fillcolour);    
    virtual void show();
    virtual void hide();
private:   
    uint16_t fillcolour;    

};
```

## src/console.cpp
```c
#include <random/rand32.h>
#include "console.h"
#include "font5x7.h"
console Console;
int console::begin()
{    
    Display.begin();    
    Controller.begin();
    Sound.begin();
    random_seed();
    return 0;
}

uint32_t console::random(uint32_t lower,uint32_t upper)
{
    return (prbs()%(upper-lower))+lower;
}
uint32_t console::prbs()
{
	// This is an unverified 31 bit PRBS generator
	// It should be maximum length but this has not been verified 
	unsigned long new_bit=0;
	static int busy=0; // need to prevent re-entrancy here
	if (!busy)
	{
		busy=1;
		new_bit= ((shift_register & (1<<27))>>27) ^ ((shift_register & (1<<30))>>30);
		new_bit= ~new_bit;
		new_bit = new_bit & 1;
		shift_register=shift_register << 1;
		shift_register=shift_register | (new_bit);
		busy=0;
	}
	return shift_register & 0x7fffffff; // return 31 LSB's 
}
void console::random_seed()
{
    // Need to find a source of random data.  This layer of BBG is meant to be 
    // hardware independent so I don't want to break that.  Will have to obtain 
    // a random seed from one of the lower layers of the BBG stack without introducing
    // additional complexity.  Hardware aware object choices: Controller, Display, Timer, Sound
    // An analogue input would be nice so this probably rules out the Display and Timer objects
    // leaving Sound and Controller.  Some variations of BBG may use an analogue joystick so 
    // perhaps a call to readAnalogue(chan_num) might be a good choice?  The channel number
    // can be defined in the controller class (as a static) and mapped appropriately within the
    // Controller object.  Will add up and scale a few reads to change more bits in the shift register
    shift_register = 0;
    while(shift_register ==0)
    {
        shift_register = sys_rand32_get();
    }
	return;
    while(shift_register == 0)
    {
        for (int i=1;i<17;i++)
            shift_register += Controller.readTemperature()<<i;
    }   
    Controller.stopADC();
}
void console::sleep(uint32_t ms)
{
	k_msleep(ms);
}
```

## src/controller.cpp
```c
#include <stdint.h>
#include <zephyr.h>
#include <sys/printk.h>
#include <device.h>
#include <drivers/gpio.h>

#include "controller.h" 
// Button configuration
#define UP_PORT_BIT 28
#define DOWN_PORT_BIT 03
#define LEFT_PORT_BIT 25 
#define RIGHT_PORT_BIT 5 
#define A_PORT_BIT 1
#define B_PORT_BIT 30
static const struct device *gpio0,*gpio1;

int controller::begin()
{
	gpio0=device_get_binding("GPIO_0");
	gpio1=device_get_binding("GPIO_1");
	if (gpio0 == NULL)
	{
		printk("Error acquiring GPIO 0 interface\n");
		return -1;
	}
	if (gpio1 == NULL)
	{
		printk("Error acquiring GPIO 1 interface\n");
		return -2;
	}
	gpio_pin_configure(gpio0, UP_PORT_BIT, GPIO_INPUT | GPIO_PULL_UP);
	gpio_pin_configure(gpio0, DOWN_PORT_BIT, GPIO_INPUT | GPIO_PULL_UP);
	gpio_pin_configure(gpio0, LEFT_PORT_BIT, GPIO_INPUT | GPIO_PULL_UP);
	gpio_pin_configure(gpio1, RIGHT_PORT_BIT, GPIO_INPUT | GPIO_PULL_UP);
	gpio_pin_configure(gpio0, A_PORT_BIT, GPIO_INPUT | GPIO_PULL_UP);
	gpio_pin_configure(gpio0, B_PORT_BIT, GPIO_INPUT | GPIO_PULL_UP);
	return 0;
}

void controller::stopADC()
{
}
uint16_t controller::getButtonState()
{
    uint16_t ReturnValue = 0;
	uint32_t port_state0 = 0;
	uint32_t port_state1 = 0;
	ReturnValue = gpio_port_get_raw(gpio0,&port_state0);
	ReturnValue = gpio_port_get_raw(gpio1,&port_state1);		
	if ((port_state0 & (1 << UP_PORT_BIT))==0)
		ReturnValue |= Up;
	if ((port_state0 & (1 << DOWN_PORT_BIT))==0)
		ReturnValue |= Down;
	if ((port_state0 & (1 << LEFT_PORT_BIT))==0)
		ReturnValue |= Left;
	if ((port_state1 & (1 << RIGHT_PORT_BIT))==0)
			ReturnValue |= Right;
	if ((port_state0 & (1 << A_PORT_BIT))==0)
			ReturnValue |= A;
	if ((port_state0 & (1 << B_PORT_BIT))==0)	
			ReturnValue |= B;		
	
    return ReturnValue;
}
uint16_t controller::readTemperature()
{
	return 0;
}
```

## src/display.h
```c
#ifndef __display_h
#define __display_h
#include <stdint.h>
#include <device.h>
#include <drivers/gpio.h>
#include <drivers/spi.h>
#define SCREEN_WIDTH 240
#define SCREEN_HEIGHT 240
class display {
public:
	int begin();
	void command(uint8_t cmd);
	void data(uint8_t data);
	void openAperture(uint16_t x1, uint16_t y1, uint16_t x2, uint16_t y2);
	void putPixel(uint16_t x, uint16_t y, uint16_t colour);
	void putImage(uint16_t x, uint16_t y, uint16_t width, uint16_t height, uint16_t *Image);
	void drawLine(uint16_t x0, uint16_t y0, uint16_t x1, uint16_t y1, uint16_t Colour);
	int iabs(int x); // simple integer version of abs for use by graphics functions        
	void drawRectangle(uint16_t x, uint16_t y, uint16_t w, uint16_t h, uint16_t Colour);
	void fillRectangle(uint16_t x,uint16_t y,uint16_t width, uint16_t height, uint16_t colour);
	void drawCircle(uint16_t x0, uint16_t y0, uint16_t radius, uint16_t Colour);
	void fillCircle(uint16_t x0, uint16_t y0, uint16_t radius, uint16_t Colour);
	void print(const char *Text, uint16_t len, uint16_t x, uint16_t y, uint16_t ForeColour, uint16_t BackColour);
	void printX2(const char *Text, uint16_t len, uint16_t x, uint16_t y, uint16_t ForeColour, uint16_t BackColour);
	void print(uint16_t number, uint16_t x, uint16_t y, uint16_t ForeColour, uint16_t BackColour);
    void printX2(uint16_t number, uint16_t x, uint16_t y, uint16_t ForeColour, uint16_t BackColour);
	uint16_t RGBToWord(uint16_t R, uint16_t G, uint16_t B);
	void drawLineLowSlope(uint16_t x0, uint16_t y0, uint16_t x1,uint16_t y1, uint16_t Colour);
	void drawLineHighSlope(uint16_t x0, uint16_t y0, uint16_t x1,uint16_t y1, uint16_t Colour);    
	void hw_test(void);
	void setBrightness(uint32_t pcnt);
	void clear();
    uint32_t mystrlen(const char *s);

};
#endif
```

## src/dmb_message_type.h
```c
#ifndef __DMB_MESSAGE_TYPE_H
#define __DMB_MESSAGE_TYPE_H
#define MAX_MESSAGE_LEN 8
typedef struct {
    uint8_t Message[MAX_MESSAGE_LEN];
} dmb_message;

extern volatile uint32_t DMBMessageReceived;
extern volatile dmb_message DMBMailBox;
extern volatile uint16_t DMBMessageSender;
extern volatile uint32_t DMBGameMessageReceived;
extern volatile dmb_message DMBGameMailBox;
extern volatile uint32_t DMBGameMessageResponseReceived;
extern volatile dmb_message DMBGameResponseMailBox;
#endif
```

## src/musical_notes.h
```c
// Rounded musical note frequencies
// 'S' is used in place of # (sharp) as that has a special meaning in C
// DS2_Eb2 is D#2 / Eb2 
#define C0	16
#define CS0_Db0	17
#define D0	18
#define DS0_Eb0	19
#define E0	21
#define F0	22
#define FS0_Gb0	23
#define G0	25
#define GS0_Ab0	26
#define A0	28
#define AS0_Bb0	29
#define B0	31
#define C1	33
#define CS1_Db1	35
#define D1	37
#define DS1_Eb1	39
#define E1	41
#define F1	44
#define FS1_Gb1	46
#define G1	49
#define GS1_Ab1	52
#define A1	55
#define AS1_Bb1	58
#define B1	62
#define C2	65
#define CS2_Db2	69
#define D2	73
#define DS2_Eb2	78
#define E2	82
#define F2	87
#define FS2_Gb2	93
#define G2	98
#define GS2_Ab2	104
#define A2	110
#define AS2_Bb2	117
#define B2	123
#define C3	131
#define CS3_Db3	139
#define D3	147
#define DS3_Eb3	156
#define E3	165
#define F3	175
#define FS3_Gb3	185
#define G3	196
#define GS3_Ab3	208
#define A3	220
#define AS3_Bb3	233
#define B3	247
#define C4	262
#define CS4_Db4	277
#define D4	294
#define DS4_Eb4	311
#define E4	330
#define F4	349
#define FS4_Gb4	370
#define G4	392
#define GS4_Ab4	415
#define A4	440
#define AS4_Bb4	466
#define B4	494
#define C5	523
#define CS5_Db5	554
#define D5	587
#define DS5_Eb5	622
#define E5	659
#define F5	698
#define FS5_Gb5	740
#define G5	784
#define GS5_Ab5	831
#define A5	880
#define AS5_Bb5	932
#define B5	988
#define C6	1047
#define CS6_Db6	1109
#define D6	1175
#define DS6_Eb6	1245
#define E6	1319
#define F6	1397
#define FS6_Gb6	1480
#define G6	1568
#define GS6_Ab6	1661
#define A6	1760
#define AS6_Bb6	1865
#define B6	1976
#define C7	2093
#define CS7_Db7	2217
#define D7	2349
#define DS7_Eb7	2489
#define E7	2637
#define F7	2794
#define FS7_Gb7	2960
#define G7	3136
#define GS7_Ab7	3322
#define A7	3520
#define AS7_Bb7	3729
#define B7	3951
#define C8	4186
#define CS8_Db8	4435
#define D8	4699
#define DS8_Eb8	4978
#define E8	5274
#define F8	5588
#define FS8_Gb8	5920
#define G8	6272
#define GS8_Ab8	6645
#define A8	7040
#define AS8_Bb8	7459
#define B8	7902
```
